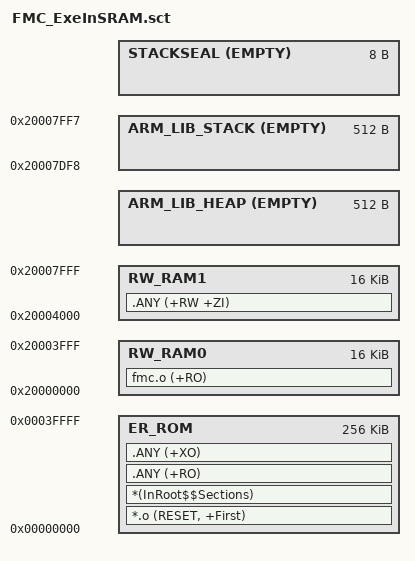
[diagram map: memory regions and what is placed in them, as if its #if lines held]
#! armclang -E --target=arm-arm-none-eabi -mcpu=cortex-m23 -xc
; command above MUST be in first line (no comment above!)

; VSCode / Arm Compiler 6 scatter-loading file
; Converted/normalized from FMC_ExeInSRAM.sct
;
; Memory layout:
;   FLASH : 0x00000000 - 0x0003FFFF (256 KB)
;   SRAM0 : 0x20000000 - 0x20003FFF ( 16 KB) : fmc.o RO executes here
;   SRAM1 : 0x20004000 - 0x20007FFF ( 16 KB) : RW/ZI, heap, stack

#ifndef FLASH_SIZE
    #define FLASH_SIZE      0x00040000
#endif

#ifndef SRAM_SIZE
    #define SRAM_SIZE       0x00008000
#endif

#ifndef STACK_SIZE
    #define STACK_SIZE      0x00000200
#endif

#ifndef HEAP_SIZE
    #define HEAP_SIZE       0x00000200
#endif

#define __FLASH_BASE        0x00000000
#define __FLASH_SIZE        FLASH_SIZE

#define __SRAM_BASE         0x20000000
#define __SRAM_SIZE         SRAM_SIZE

#define __STACK_SIZE        STACK_SIZE
#define __HEAP_SIZE         HEAP_SIZE

#if defined (__ARM_FEATURE_CMSE) && (__ARM_FEATURE_CMSE == 3U)
#define __STACKSEAL_SIZE    (8)
#else
#define __STACKSEAL_SIZE    (0)
#endif

#define __STACK_TOP         (__SRAM_BASE + __SRAM_SIZE - __STACKSEAL_SIZE)
#define __HEAP_BASE         (AlignExpr(+0, 8))

#define __RO_BASE           (__FLASH_BASE)
#define __RO_SIZE           (__FLASH_SIZE)

#define __RW_BASE           (__SRAM_BASE)
#define __SRAM_SIZE0        (SRAM_SIZE / 2)
#define __SRAM_SIZE1        (SRAM_SIZE / 2)

LR_ROM __RO_BASE __RO_SIZE
{
    ; General RO/XO remains in Flash.
    ER_ROM __RO_BASE __RO_SIZE
    {
        *.o (RESET, +First)
        *(InRoot$$Sections)
        .ANY (+RO)
        .ANY (+XO)
    }

    ; Explicitly place the FMC object's RO sections in the first 16 KB SRAM.
    ; The load image is automatically kept in LR_ROM (Flash), and Arm's
    ; scatter-load startup copies it to this execution address before main().
    RW_RAM0 __RW_BASE __SRAM_SIZE0
    {
        fmc.o (+RO)
    }

    ; All RW/ZI data uses the upper 16 KB SRAM.
    RW_RAM1 (__RW_BASE + __SRAM_SIZE0) __SRAM_SIZE1
    {
        .ANY (+RW +ZI)
    }

#if __HEAP_SIZE > 0
    ARM_LIB_HEAP __HEAP_BASE EMPTY __HEAP_SIZE
    {
    }
#endif

    ARM_LIB_STACK __STACK_TOP EMPTY -__STACK_SIZE
    {
    }

#if defined (__ARM_FEATURE_CMSE) && (__ARM_FEATURE_CMSE == 3U)
    STACKSEAL +0 EMPTY __STACKSEAL_SIZE
    {
    }
#endif
}
